# PIC32CZ8110CA80208 device description
Architecture: CORTEX-M7; Family: PIC32C; Series: PIC32CZCA80
Registers are 32-bit, read-write, reset 0x0 unless marked. A register's access mark holds for its fields unless they carry their own. Offsets are from the block's base; [hi:lo] are bit positions; {n}, {i} and the like mark numbered series; <NAME> marks a mode.

## GCLK — Generic Clock Generator
Instances: GCLK 0x44050000
0x00 CTRLA 8-bit (WSYNC) — Control
  [0] SWRST — Software Reset
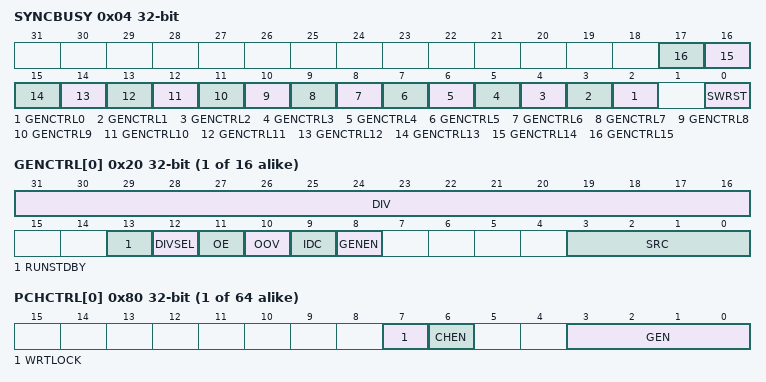
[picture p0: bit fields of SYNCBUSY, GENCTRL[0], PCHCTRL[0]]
0x04 SYNCBUSY ro — Synchronization Busy
  [n+2] GENCTRL{n} (n=0..15) — Generic Clock Generator Control {n} Synchronization Busy bit
  [0] SWRST — Software Reset Synchronization Busy bit
{0x20+4i} GENCTRL[{i}] (i=0..15) (WSYNC) — Generic Clock Generator Control
  [31:16] DIV — Division Factor
  [13] RUNSTDBY — Run in Standby
  [12] DIVSEL — Divide Selection
    0=DIV1 (Divide input directly by divider factor); 1=DIV2 (Divide input by 2^(divider factor+ 1))
  [11] OE — Output Enable
  [10] OOV — Output Off Value
  [9] IDC — Improve Duty Cycle
  [8] GENEN — Generic Clock Generator Enable
  [3:0] SRC — Source Select
    0=XOSC (XOSC0 oscillator output); 1=GCLKIN (Generator input pad); 2=GCLKGEN1 (Generic clock generator 1 output); 3=OSCULP32K (OSCULP32K oscillator output); 4=XOSC32K (XOSC32K oscillator output); 5=DFLL (DFLL output); {v}=PLL0_{v-5} (PLL0 output {v-5}) (v=6..9); 10=PLL1_1 (Frac Divider PLL1 output 1); 11=PLL1_2 (Frac Divider PLL1 output 2); 12=PLL1_3 (PLL1 output 3); 13=PLL1_4 (PLL1 output 4)
{0x80+4i} PCHCTRL[{i}] (i=0..63) — Peripheral Clock Control
  [7] WRTLOCK — Write Lock
  [6] CHEN — Channel Enable
  [3:0] GEN — Generic Clock Generator
    {v}=GCLK{v} (Generic clock generator {v}) (v=0..15)

## ITM — Instrumentation Trace Macrocell
Instances: ITM 0xE0041000
{0x0+4i} PORT[{i}] (i=0..31) wo reset not defined — ITM Stimulus Port Registers
  [7:0] PORT <BYTE>, [15:0] PORT <HWORD>, [31:0] PORT <WORD>
0xE00 TER reset not defined — ITM Trace Enable Register
0xE40 TPR reset not defined — ITM Trace Privilege Register
  [3:0] PRIVMASK
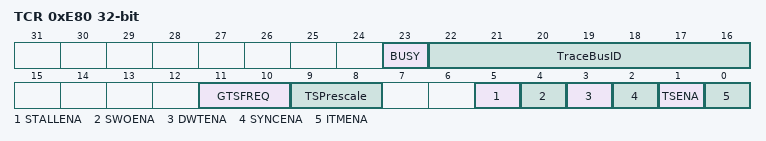
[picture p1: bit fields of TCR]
0xE80 TCR reset not defined — ITM Trace Control Register
  [23] BUSY, [22:16] TraceBusID, [11:10] GTSFREQ, [9:8] TSPrescale, [5] STALLENA, [4] SWOENA, [3] DWTENA, [2] SYNCENA, [1] TSENA, [0] ITMENA
0xEF8 IWR wo reset not defined — ITM Integration Write Register
  [0] ATVALIDM
0xEFC IRR ro reset not defined — ITM Integration Read Register
  [0] ATREADYM

## MCLK — Main Clock
Instances: MCLK 0x44052000
0x00 INTENCLR (atomic clear) — Interrupt Enable Clear
  [0] CKRDY — Clock Ready Interrupt Enable
0x04 INTENSET (atomic set) — Interrupt Enable Set
  [0] CKRDY — Clock Ready Interrupt Enable
0x08 INTFLAG reset 0x1 (atomic clear) — Interrupt Flag Status and Clear
  [0] CKRDY — Clock Ready
{0xC+4i} CLKDIV[{i}] (i=0..1) — Clock Divider Control
  [7:0] DIV — Clock Domain Division Factor
    1=Divide by 1; 2=Divide by 2; 4=Divide by 4; 8=Divide by 8; 16=Divide by 16; 32=Divide by 32; 64=Divide by 64; 128=Divide by 128
{0x3C+4i} CLKMSK[{i}] (i=0..8) — Peripheral Clock Enable Mask
  [31:0] MASK

## MCRAMC — Multi-Channel RAM Controller
Instances: MCRAMC 0x44822000
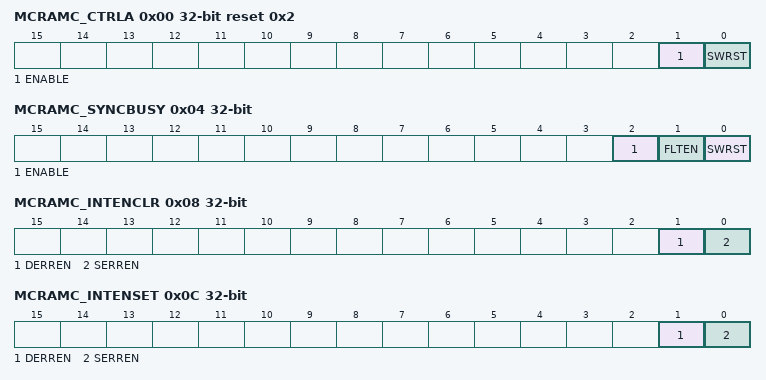
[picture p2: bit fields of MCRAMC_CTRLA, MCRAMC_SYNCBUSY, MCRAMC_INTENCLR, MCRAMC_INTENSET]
0x00 MCRAMC_CTRLA reset 0x2 — Control Enable A Register
  [1] ENABLE — ECC Decoder Enable
    0=ECC decoding is disabled; 1=ECC decoding is enabled
  [0] SWRST — Software Reset
    0=No effect; 1=Reset the MCRAMC. A software-triggered hardware reset of the MCRAMC user interface is performed.
0x04 MCRAMC_SYNCBUSY ro — Sync Busy Register
  [2] ENABLE — ECC Decoder Enable busy bit
  [1] FLTEN — Fault Injection Enabled busy bit
  [0] SWRST — Software reset busy bit
0x08 MCRAMC_INTENCLR (atomic clear) — Interrupt Enable Clear Register
  [1] DERREN — Double Bit Error Interrupt Enable, Clear
  [0] SERREN — Single Bit Error Interrupt Enable, Clear
0x0C MCRAMC_INTENSET (atomic set) — Interrupt Enable Set Register
  [1] DERREN — Double Bit Error Interrupt Enable, Set
  [0] SERREN — Single Bit Error Interrupt Enable, Set
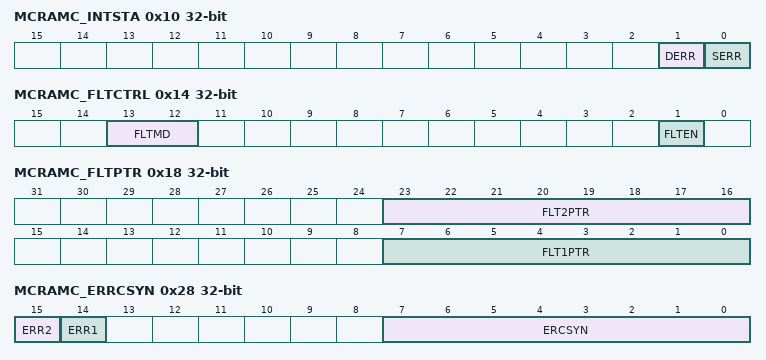
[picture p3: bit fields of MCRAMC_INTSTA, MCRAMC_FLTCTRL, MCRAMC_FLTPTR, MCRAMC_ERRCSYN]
0x10 MCRAMC_INTSTA (atomic clear) — Interrupt Status Register
  [1] DERR — Double Bit Error
  [0] SERR — Single Bit Error
0x14 MCRAMC_FLTCTRL — Fault Injection Control Register
  [13:12] FLTMD — Fault Injection Mode
  [1] FLTEN — Fault Injection Enabled
    0=Disables fault injection; 1=Enables fault injection at FLTADR address offset as selected by FLTMD and FLTxPTR
0x18 MCRAMC_FLTPTR — Fault Injection Pointer Register
  [23:16] FLT2PTR — Double Fault Injection Bit Pointer
  [7:0] FLT1PTR — Single Fault Injection Bit Pointer
0x1C MCRAMC_FLTADR — Fault Injection Address Register
  [23:0] FLTADR — Fault Address Offset
0x20 MCRAMC_ERRCADR ro — Error Capture Address Register
  [23:0] ERCADR — ECC SECDED Error Capture Address
0x24 MCRAMC_ERRCPAR ro — Error Capture Parity Register
  [7:0] ERCPAR — ECC SECDED Error Capture Parity
0x28 MCRAMC_ERRCSYN ro — Error Capture Syndrome Register
  [15] ERR2 — ECC Double Bit Error
    0=Not a Double bit error; 1=Double bit error
  [14] ERR1 — ECC Single Bit Error
  [7:0] ERCSYN — ECC SECDED Error Capture Syndrome
    0=Not a Single bit error; 1=Single bit error

## Notices in the file
Copyright (c) 2021 Microchip Technology Inc.
SPDX-License-Identifier: Apache-2.0
Licensed under the Apache License, Version 2.0 (the "License");
you may not use this file except in compliance with the License.
You may obtain a copy of the License at
http://www.apache.org/licenses/LICENSE-2.0
Unless required by applicable law or agreed to in writing, software
distributed under the License is distributed on an "AS IS" BASIS,
WITHOUT WARRANTIES OR CONDITIONS OF ANY KIND, either express or implied.
See the License for the specific language governing permissions and
limitations under the License.
